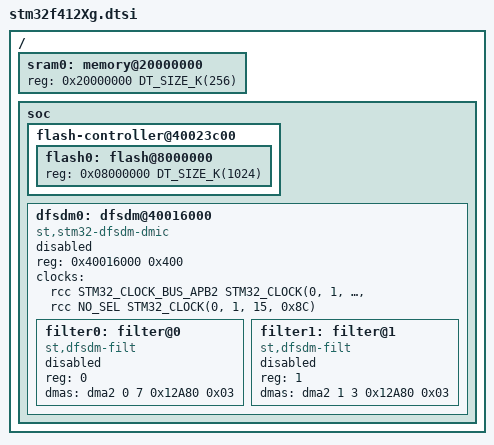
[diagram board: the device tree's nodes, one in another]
/*
 * Copyright (c) 2018 Linaro Limited
 *
 * SPDX-License-Identifier: Apache-2.0
 */

#include <mem.h>
#include <st/f4/stm32f412.dtsi>

/ {
	sram0: memory@20000000 {
		reg = <0x20000000 DT_SIZE_K(256)>;
	};

	soc {
		flash-controller@40023c00 {
			flash0: flash@8000000 {
				reg = <0x08000000 DT_SIZE_K(1024)>;
			};
		};
		dfsdm0: dfsdm@40016000 {
			compatible = "st,stm32-dfsdm-dmic";
			status = "disabled";

			reg = <0x40016000 0x400>;
			#address-cells = <1>;
			#size-cells = <0>;

			clocks = <&rcc STM32_CLOCK_BUS_APB2 STM32_CLOCK(0, 1, 31, 0x8C)>,   // DFSDM kernel clock: Default PCLK2 (0), or SYSCLK (1)
			/*<&rcc STM32_SRC_PLLI2S_R STM32_CLOCK(0, 3, 25, 0x8C)>,*/   // TODO: do we need to set PLLI2S1 to PLLI2S_R here, or is that done somewhere else???
			<&rcc NO_SEL STM32_CLOCK(0, 1, 15, 0x8C)>;                 // DFSDM audio clock: Default PLLI2S1 (0), or PLLI2S2 (1)

			clock-names = "dfsdm", "audio";

			filter0: filter@0 {
				compatible = "st,dfsdm-filt";
				reg = <0>;
				// TODO: interrupts
				dmas = <&dma2 0 7 0x12A80 0x03>;
				status = "disabled";
			};
	
			filter1: filter@1 {
				compatible = "st,dfsdm-filt";
				reg = <1>;
				// TODO: interrupts
				dmas = <&dma2 1 3 0x12A80 0x03>;
				status = "disabled";
			};
		};
	};
};
